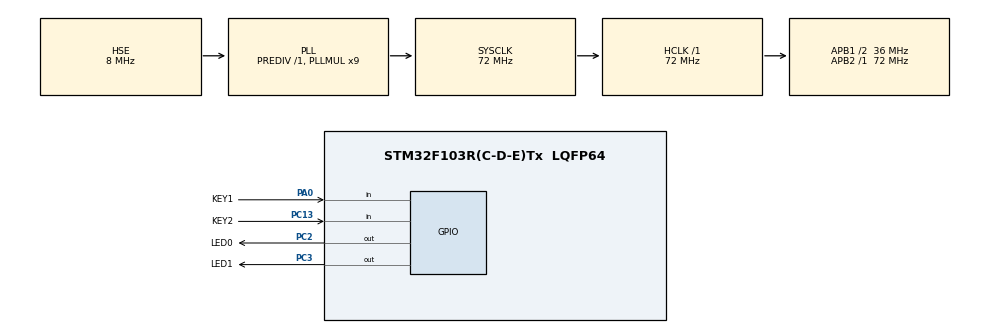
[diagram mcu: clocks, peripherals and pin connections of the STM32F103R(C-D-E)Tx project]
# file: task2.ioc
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Mcu.Family=STM32F1
Mcu.Name=STM32F103R(C-D-E)Tx
Mcu.Package=LQFP64
NVIC.PriorityGroup=NVIC_PRIORITYGROUP_4
PA0-WKUP.GPIO_Label=KEY1
PA0-WKUP.Signal=GPIO_Input
PA13.Mode=Serial_Wire
PA13.Signal=SYS_JTMS-SWDIO
PA14.Mode=Serial_Wire
PA14.Signal=SYS_JTCK-SWCLK
PC13-TAMPER-RTC.GPIO_Label=KEY2
PC13-TAMPER-RTC.Signal=GPIO_Input
PC2.GPIO_Label=LED0
PC2.PinState=GPIO_PIN_SET
PC2.Signal=GPIO_Output
PC3.GPIO_Label=LED1
PC3.PinState=GPIO_PIN_SET
PC3.Signal=GPIO_Output
PD0-OSC_IN.Mode=HSE-External-Oscillator
PD0-OSC_IN.Signal=RCC_OSC_IN
PD1-OSC_OUT.Mode=HSE-External-Oscillator
PD1-OSC_OUT.Signal=RCC_OSC_OUT
ProjectManager.HeapSize=0x200
ProjectManager.StackSize=0x400
ProjectManager.TargetToolchain=MDK-ARM V5.32
RCC.AHBFreq_Value=72000000
RCC.APB1CLKDivider=RCC_HCLK_DIV2
RCC.APB1Freq_Value=36000000
RCC.APB1TimFreq_Value=72000000
RCC.APB2Freq_Value=72000000
RCC.APB2TimFreq_Value=72000000
RCC.HCLKFreq_Value=72000000
RCC.PLLMUL=RCC_PLL_MUL9
RCC.PLLSourceVirtual=RCC_PLLSOURCE_HSE
RCC.SYSCLKFreq_VALUE=72000000
RCC.SYSCLKSource=RCC_SYSCLKSOURCE_PLLCLK
RCC.USBFreq_Value=72000000
board=custom

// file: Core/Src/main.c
/* USER CODE BEGIN Header */
/**
  ******************************************************************************
  * @file           : main.c
  * @brief          : Main program body
  ******************************************************************************
  * @attention
  *
  * Copyright (c) 2025 STMicroelectronics.
  * All rights reserved.
  *
  * This software is licensed under terms that can be found in the LICENSE file
  * in the root directory of this software component.
  * If no LICENSE file comes with this software, it is provided AS-IS.
  *
  ******************************************************************************
  */
/* USER CODE END Header */
#include "main.h"
#include "gpio.h"

/* USER CODE BEGIN PV */
uint8_t state = 0;//状态机状态变量，初始状态为0
uint32_t last_tick = 0;//用于记录上一次的系统时间
uint8_t Pin_enum = 0;//用于记录当前点亮的LED灯，0表示LED0，1表示LED1
GPIO_PinState key1_last_state = GPIO_PIN_RESET;//用于记录按键一的上一次状态
GPIO_PinState key2_last_state = GPIO_PIN_RESET;//用于记录按键二的上一次状态
GPIO_PinState key1_current_state = GPIO_PIN_RESET;//用于记录按键一的当前状态
GPIO_PinState key2_current_state = GPIO_PIN_RESET;//用于记录按键二的当前状态
/* USER CODE END PV */

void SystemClock_Config(void);

int main(void)
{

  /* MCU Configuration--------------------------------------------------------*/

  /* Reset of all peripherals, Initializes the Flash interface and the Systick. */
  HAL_Init();

  /* Configure the system clock */
  SystemClock_Config();

  /* Initialize all configured peripherals */
  MX_GPIO_Init();

  /* Infinite loop */
  /* USER CODE BEGIN WHILE */
  while (1)
  {
    /* *************************** 读取按键状态 ***************************************** */
    key1_current_state = HAL_GPIO_ReadPin(KEY1_GPIO_Port,KEY1_Pin);//记录当前按键一的状态
    key2_current_state = HAL_GPIO_ReadPin(KEY2_GPIO_Port,KEY2_Pin);//记录当前按键二的状态
    /* ******************************************************************************** */

    /* *************************** 状态机设计 ***************************************** */
    if(key1_current_state == GPIO_PIN_SET && key2_current_state == GPIO_PIN_SET)//若两个按键如果都按下(不是同时！！！)
    {
      //记录当前按键状态为上一次按键状态
      key1_last_state = key1_current_state;
      key2_last_state = key2_current_state;
      //让双灯灭
      //注意：只有两个引脚在同一个端口才能进行位或操作
      HAL_GPIO_WritePin(GPIOC,LED0_Pin|LED1_Pin,GPIO_PIN_SET);
      //状态切换
      state = 1;
      //初始化引脚状态
      Pin_enum = 0;
    }
    else if (key1_current_state != key1_last_state)//若按键一的当前状态与上一次状态不同
    {
      //立刻记录当前按键状态作为上一次按键状态
      key1_last_state = key1_current_state;
      if(key1_current_state == GPIO_PIN_SET)//若按键状态为按下且上次状态与之不同(即上一次为低电平)
      {
        //让双灯灭
        //注意：只有两个引脚在同一个端口才能进行位或操作
        HAL_GPIO_WritePin(GPIOC,LED0_Pin|LED1_Pin,GPIO_PIN_SET);
        //状态切换
        state = 2;
      }
    }
    else if (key2_current_state != key2_last_state)//若按键二的当前状态与上一次状态不同
    {
      //立刻记录当前按键状态作为上一次按键状态
      key2_last_state = key2_current_state;
      if(key2_current_state == GPIO_PIN_SET)//若按键状态为按下且上次状态与之不同(即上一次为低电平)
      {
        //让双灯灭
        //注意：只有两个引脚在同一个端口才能进行位或操作
        HAL_GPIO_WritePin(GPIOC,LED0_Pin|LED1_Pin,GPIO_PIN_SET);
        //状态切换
        state = 3;
      }
    }
    /* ******************************************************************************** */

    /* ************************************ 状态机任务执行区域 ******************************************** */
    //全程使用非阻塞延时，以免影响按键检测
    if(state == 0)//初始状态，双灯灭
    {
      HAL_GPIO_WritePin(GPIOC,LED0_Pin|LED1_Pin,GPIO_PIN_SET);
    }
    else if (state == 1)//交替闪烁，周期是500ms
    {
      if(HAL_GetTick() - last_tick >= 250)
      {
        if(Pin_enum == 0)
        {
          HAL_GPIO_TogglePin(LED0_GPIO_Port,LED0_Pin);
          HAL_GPIO_WritePin(LED1_GPIO_Port,LED1_Pin,GPIO_PIN_RESET);
          Pin_enum = 1;
        }
        else
        {
          HAL_GPIO_TogglePin(LED1_GPIO_Port,LED1_Pin);
          HAL_GPIO_WritePin(LED0_GPIO_Port,LED0_Pin,GPIO_PIN_RESET);
          Pin_enum = 0;
        }
        last_tick = HAL_GetTick();
      }
    }
    else if (state == 2)//LED0闪烁，周期是1s
    {
      if(HAL_GetTick() - last_tick >= 500)
      {
        HAL_GPIO_TogglePin(LED0_GPIO_Port,LED0_Pin);
        last_tick = HAL_GetTick();
      }
    }
    else if (state == 3)//LED1闪烁，周期是0.5s
    {
      if(HAL_GetTick() - last_tick >= 250)
      {
        HAL_GPIO_TogglePin(LED1_GPIO_Port,LED1_Pin);
        last_tick = HAL_GetTick();
      }
    }
  }
  /* ******************************************************************************** */
}

void SystemClock_Config(void)
{
  RCC_OscInitTypeDef RCC_OscInitStruct = {0};
  RCC_ClkInitTypeDef RCC_ClkInitStruct = {0};

  /** Initializes the RCC Oscillators according to the specified parameters
  * in the RCC_OscInitTypeDef structure.
  */
  RCC_OscInitStruct.OscillatorType = RCC_OSCILLATORTYPE_HSE;
  RCC_OscInitStruct.HSEState = RCC_HSE_ON;
  RCC_OscInitStruct.HSEPredivValue = RCC_HSE_PREDIV_DIV1;
  RCC_OscInitStruct.HSIState = RCC_HSI_ON;
  RCC_OscInitStruct.PLL.PLLState = RCC_PLL_ON;
  RCC_OscInitStruct.PLL.PLLSource = RCC_PLLSOURCE_HSE;
  RCC_OscInitStruct.PLL.PLLMUL = RCC_PLL_MUL9;
  if (HAL_RCC_OscConfig(&RCC_OscInitStruct) != HAL_OK)
  {
    Error_Handler();
  }

  /** Initializes the CPU, AHB and APB buses clocks
  */
  RCC_ClkInitStruct.ClockType = RCC_CLOCKTYPE_HCLK|RCC_CLOCKTYPE_SYSCLK
                              |RCC_CLOCKTYPE_PCLK1|RCC_CLOCKTYPE_PCLK2;
  RCC_ClkInitStruct.SYSCLKSource = RCC_SYSCLKSOURCE_PLLCLK;
  RCC_ClkInitStruct.AHBCLKDivider = RCC_SYSCLK_DIV1;
  RCC_ClkInitStruct.APB1CLKDivider = RCC_HCLK_DIV2;
  RCC_ClkInitStruct.APB2CLKDivider = RCC_HCLK_DIV1;

  if (HAL_RCC_ClockConfig(&RCC_ClkInitStruct, FLASH_LATENCY_2) != HAL_OK)
  {
    Error_Handler();
  }
}

void Error_Handler(void)
{
  __disable_irq();
  while (1)
  {
  }
}
